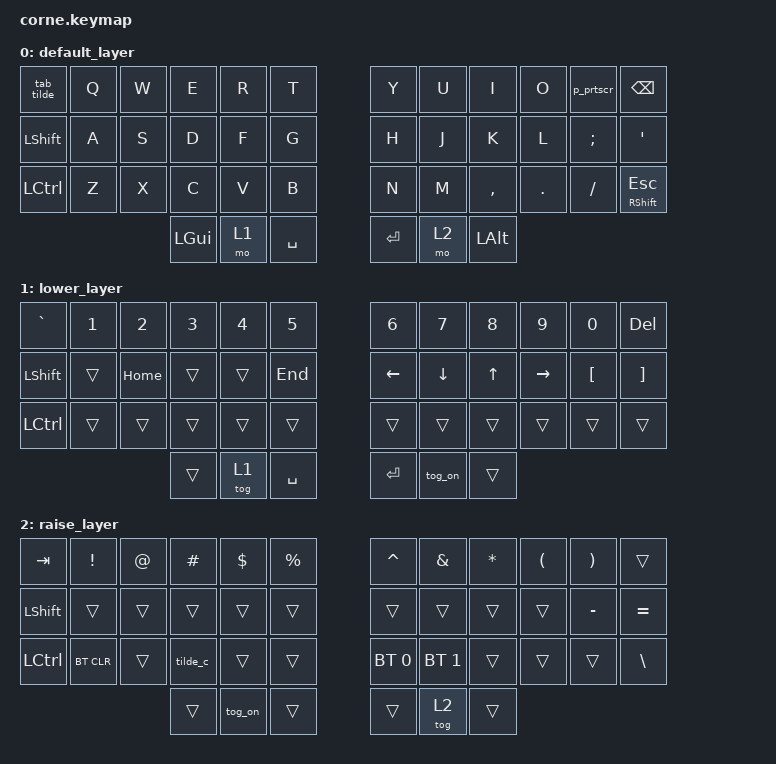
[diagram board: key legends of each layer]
/*
 * Copyright (c) 2020 The ZMK Contributors
 *
 * SPDX-License-Identifier: MIT
 */

#include <behaviors.dtsi>
#include <dt-bindings/zmk/keys.h>
#include <dt-bindings/zmk/bt.h>

/ {
    behaviors {
	ht_tp: homerow_mods {
            compatible = "zmk,behavior-hold-tap";
            #binding-cells = <2>;
            tapping-term-ms = <200>;
            quick-tap-ms = <0>;
            flavor = "tap-preferred";
            bindings = <&kp>, <&kp>;
        };

        tab_tilde: tab_tilde {
            compatible = "zmk,behavior-mod-morph";
            #binding-cells = <0>;
            bindings = <&kp TAB>, <&kp TILDE>;
            mods = <(MOD_LSFT|MOD_RSFT)>;
        };

        p_prtscr: prtscr {
            compatible = "zmk,behavior-mod-morph";
            #binding-cells = <0>;
            bindings = <&kp P>, <&kp PSCRN>;
            mods = <(MOD_LGUI)>;
        };

	tog_on: toggle_layer_on_only {
            compatible = "zmk,behavior-toggle-layer";
            #binding-cells = <1>;
            display-name = "Toggle Layer On";
            toggle-mode = "on";
        };
    };

    macros {
        tilde_c: tilde_c {
	    compatible = "zmk,behavior-macro";
            #binding-cells = <0>;
            bindings = <&macro_press &kp RALT>
                , <&macro_tap &kp COMMA>
                , <&macro_release &kp RALT>
                , <&macro_tap &kp C>
                ;
        };
    };

    keymap {
        compatible = "zmk,keymap";

        default_layer {
        // -----------------------------------------------------------------------------------------
        // |  TAB |  Q  |  W  |  E  |  R  |  T  |   |  Y  |  U   |  I  |  O  |  P  | BSPC      |
        // | SHFT |  A  |  S  |  D  |  F  |  G  |   |  H  |  J   |  K  |  L  |  ;  |  '        |
        // | CTRL |  Z  |  X  |  C  |  V  |  B  |   |  N  |  M   |  ,  |  .  |  /  | ESC/SHIFT |
        //                    | GUI | LWR | SPC |   | ENT | RSE  | ALT |
        bindings = <
           &tab_tilde  &kp Q    &kp W    &kp  E &kp R &kp T   &kp Y   &kp  U   &kp I     &kp O   &p_prtscr &kp BACKSPACE
           &kp LSHIFT  &kp A    &kp S    &kp  D &kp F &kp G   &kp H   &kp  J   &kp K     &kp L   &kp SEMI  &kp SQT
           &kp LCTRL   &kp Z    &kp X    &kp  C &kp V &kp B   &kp N   &kp  M   &kp COMMA &kp DOT &kp FSLH  &ht_tp RSHIFT ESC
                       &kp LGUI &mo 1    &kp SPACE    &kp RET &mo 2   &kp LALT
        >;
        };

        lower_layer {
        // -----------------------------------------------------------------------------------------
        // | GRAVE |  1  |   2  |  3  |  4  |  5  |   |  6  |  7  |  8  |  9  |  0  | DEL |
        // | SHFT  |     | HOME |     |     | END |   | LFT | DWN |  UP | RGT |  [  |  ]  |
        // | CTRL  |     |      |     |     |     |   |     |     |     |     |     |     |
        //                      |     |     | SPC |   | ENT |     |     |
        bindings = <
           &kp GRAVE  &kp N1 &kp N2   &kp N3 &kp N4 &kp N5       &kp N6   &kp N7   &kp N8 &kp N9    &kp N0   &kp DEL
           &kp LSHIFT &trans &kp HOME &trans &trans &kp END      &kp LEFT &kp DOWN &kp UP &kp RIGHT &kp LBKT &kp RBKT
           &kp LCTRL  &trans &trans   &trans &trans &trans       &trans   &trans   &trans &trans    &trans   &trans
                                      &trans &tog 1 &kp SPACE    &kp RET  &tog_on  &trans
        >;
        };
        
        raise_layer {
        // -----------------------------------------------------------------------------------------
        // |  TAB |  !     |  @  |  #  |  $  |  %  |      |  ^  |  &  |   *    |  (  |  )  |   |
        // | SHFT |        |     |     |     |     |      |     |     |        |     |  -  | = |
        // | CTRL | BT_CLR |     |  ç  |     |     |      | BT1 | BT2 |        |     |     | \ |
        //                 |     |     |     |     |      |     |     |        |
        bindings = <
           &kp TAB    &kp EXCL    &kp AT &kp HASH &kp DOLLAR &kp PRCNT      &kp CARET     &kp AMPS       &kp STAR   &kp LPAR  &kp RPAR  &trans
           &kp LSHIFT &trans      &trans &trans   &trans     &trans         &trans        &trans         &trans     &trans    &kp MINUS &kp EQUAL 
           &kp LCTRL  &bt BT_CLR  &trans &tilde_c &trans     &trans         &bt BT_SEL 0  &bt BT_SEL 1   &trans     &trans    &trans    &kp BSLH
                                         &trans   &tog_on    &trans         &trans        &tog 2         &trans 
        >;
        };
    };
};

